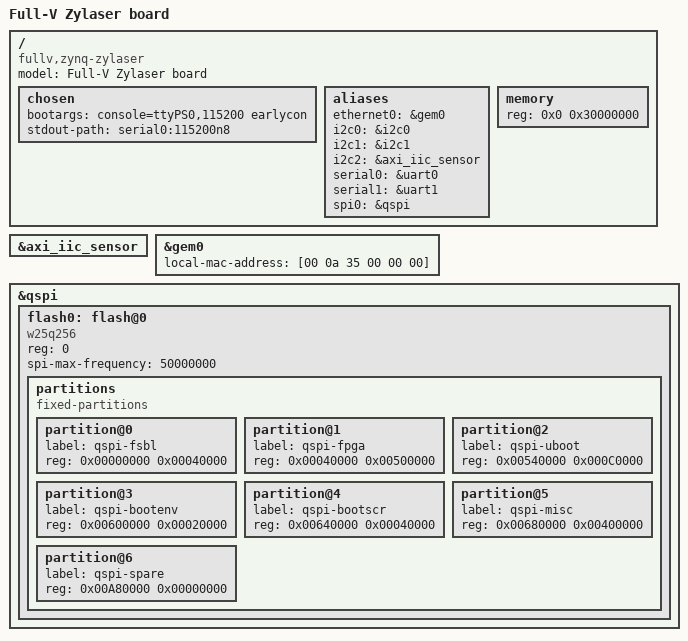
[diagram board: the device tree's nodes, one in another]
/*
 * CAUTION: This file is automatically generated by Xilinx.
 * Version:  
 * Today is: Tue Oct 27 21:13:41 2020
 */

/dts-v1/;
#include "zynq-7000.dtsi"
#include "zynq-zylaser/pl.dtsi"
#include "zynq-zylaser/pcw.dtsi"

/ {
	model = "Full-V Zylaser board";
	compatible = "fullv,zynq-zylaser", "xlnx,zynq-7000";

	chosen {
		bootargs = "console=ttyPS0,115200 earlycon";
		stdout-path = "serial0:115200n8";
	};

	aliases {
		ethernet0 = &gem0;
		i2c0 = &i2c0;
		i2c1 = &i2c1;
		i2c2 = &axi_iic_sensor;
		serial0 = &uart0;
		serial1 = &uart1;
		spi0 = &qspi;
	};

	memory {
		device_type = "memory";
		reg = <0x0 0x30000000>;
	};
};

&axi_iic_sensor {
	status = "okay";
};

&gem0 {
	local-mac-address = [00 0a 35 00 00 00];
};

&qspi {
	#address-cells = <1>;
	#size-cells = <0>;

	flash0: flash@0 {
		compatible = "w25q256";
		reg = <0>;
		spi-max-frequency = <50000000>;

		partitions {
			#address-cells = <1>;
			#size-cells = <1>;
			compatible = "fixed-partitions";

			partition@0 {
				label = "qspi-fsbl";
				reg = <0x00000000 0x00040000>;
			};
			partition@1 {
				label = "qspi-fpga";
				reg = <0x00040000 0x00500000>;
			};
			partition@2 {
				label = "qspi-uboot";
				reg = <0x00540000 0x000C0000>;
			};
			partition@3 {
				label = "qspi-bootenv";
				reg = <0x00600000 0x00020000>;
			};
			partition@4 {
				label = "qspi-bootscr";
				reg = <0x00640000 0x00040000>;
			};
			partition@5 {
				label = "qspi-misc";
				reg = <0x00680000 0x00400000>;
			};
			partition@6 {
				label = "qspi-spare";
				reg = <0x00A80000 0x00000000>;
			};
		};
	};
};
